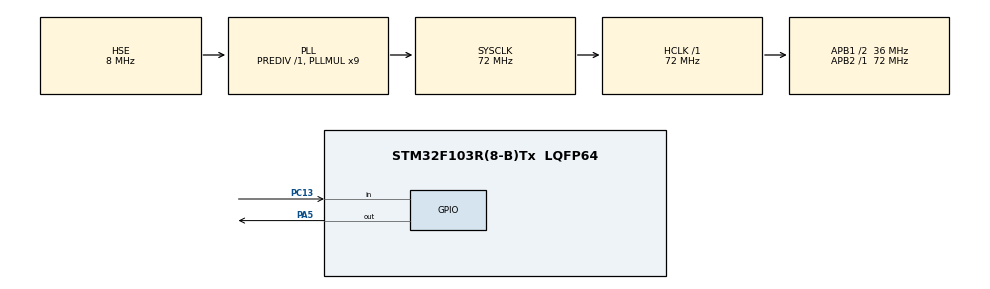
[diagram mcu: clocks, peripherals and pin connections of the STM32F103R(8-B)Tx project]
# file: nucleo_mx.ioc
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Mcu.Family=STM32F1
Mcu.Name=STM32F103R(8-B)Tx
Mcu.Package=LQFP64
NVIC.PriorityGroup=NVIC_PRIORITYGROUP_4
PA13.Mode=Serial_Wire
PA13.Signal=SYS_JTMS-SWDIO
PA14.Mode=Serial_Wire
PA14.Signal=SYS_JTCK-SWCLK
PA5.GPIO_Speed=GPIO_SPEED_FREQ_LOW
PA5.Signal=GPIO_Output
PC13-TAMPER-RTC.GPIO_PuPd=GPIO_NOPULL
PC13-TAMPER-RTC.Signal=GPIO_Input
PC14-OSC32_IN.Mode=LSE-External-Oscillator
PC14-OSC32_IN.Signal=RCC_OSC32_IN
PC15-OSC32_OUT.Mode=LSE-External-Oscillator
PC15-OSC32_OUT.Signal=RCC_OSC32_OUT
PD0-OSC_IN.Mode=HSE-External-Clock-Source
PD0-OSC_IN.Signal=RCC_OSC_IN
PD1-OSC_OUT.Mode=HSE-External-Clock-Source
PD1-OSC_OUT.Signal=RCC_OSC_OUT
ProjectManager.HeapSize=0x200
ProjectManager.StackSize=0x400
ProjectManager.TargetToolchain=Other Toolchains (GPDSC)
RCC.AHBFreq_Value=72000000
RCC.APB1CLKDivider=RCC_HCLK_DIV2
RCC.APB1Freq_Value=36000000
RCC.APB1TimFreq_Value=72000000
RCC.APB2Freq_Value=72000000
RCC.APB2TimFreq_Value=72000000
RCC.HCLKFreq_Value=72000000
RCC.PLLMUL=RCC_PLL_MUL9
RCC.PLLSourceVirtual=RCC_PLLSOURCE_HSE
RCC.SYSCLKFreq_VALUE=72000000
RCC.SYSCLKSource=RCC_SYSCLKSOURCE_PLLCLK
RCC.USBFreq_Value=72000000
board=NUCLEO-F103RB

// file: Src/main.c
/* USER CODE BEGIN Header */
/**
  ******************************************************************************
  * @file           : main.c
  * @brief          : Main program body
  ******************************************************************************
  * @attention
  *
  * <h2><center>&copy; Copyright (c) 2023 STMicroelectronics.
  * All rights reserved.</center></h2>
  *
  * This software component is licensed by ST under BSD 3-Clause license,
  * the "License"; You may not use this file except in compliance with the
  * License. You may obtain a copy of the License at:
  *                        opensource.org/licenses/BSD-3-Clause
  *
  ******************************************************************************
  */
/* USER CODE END Header */
#include "main.h"

void SystemClock_Config(void);
static void MX_GPIO_Init(void);

/* USER CODE BEGIN 0 */
#include <sfc/board.h>
#include <sfc/periphery/gpio.h>

// TODO: need better STM32CubeMX integration
typedef struct
{
    sfc_gpio_port_t dev;
    GPIO_TypeDef* core;
} stm32_gpio_t;

static void set(const sfc_gpio_port_t *port, uint32_t pin, sfc_gpio_pin_state_t state)
{
    const stm32_gpio_t *gpio = (stm32_gpio_t*)port;

    HAL_GPIO_WritePin(gpio->core, (1 << pin), state == SFC_GPIO_PIN_STATE_LOW  ? GPIO_PIN_RESET : GPIO_PIN_SET);
}

static sfc_gpio_pin_state_t get(const sfc_gpio_port_t *port, uint32_t pin)
{
    const stm32_gpio_t *gpio = (stm32_gpio_t*)port;

    GPIO_PinState state = HAL_GPIO_ReadPin(gpio->core, (1 << pin));

    return state == GPIO_PIN_SET ? SFC_GPIO_PIN_STATE_HIGH : SFC_GPIO_PIN_STATE_LOW;
}

static sfc_gpio_ops_t ops =
{
    .set = set,
    .get = get,
    .cfg = NULL
};
stm32_gpio_t portA = {{&portA, &ops}, GPIOA};
sfc_gpio_pin_t led_pin = {&portA.dev, 5};
stm32_gpio_t portC = {{&portC, &ops}, GPIOC};
sfc_gpio_pin_t btn_pin = {&portC.dev, 13};
#if 0
/* USER CODE END 0 */

int main(void)
{
  /* USER CODE BEGIN 1 */
}
#endif
void sfc_board_init()
{
  /* USER CODE END 1 */

  /* MCU Configuration--------------------------------------------------------*/

  /* Reset of all peripherals, Initializes the Flash interface and the Systick. */
  HAL_Init();

  /* Configure the system clock */
  SystemClock_Config();

  /* Initialize all configured peripherals */
  MX_GPIO_Init();
  /* USER CODE BEGIN 2 */

  sfc_gpio_assign_port(SFC_GPIO_CORE_1, &portA.dev);
  sfc_gpio_assign_port(SFC_GPIO_CORE_3, &portC.dev);
  /* USER CODE END 2 */

  /* Infinite loop */
  /* USER CODE BEGIN WHILE */
#if 0
  while (1)
  {
    /* USER CODE END WHILE */

    /* USER CODE BEGIN 3 */
  }
#endif
  /* USER CODE END 3 */
}

void SystemClock_Config(void)
{
  RCC_OscInitTypeDef RCC_OscInitStruct = {0};
  RCC_ClkInitTypeDef RCC_ClkInitStruct = {0};

  /** Initializes the RCC Oscillators according to the specified parameters
  * in the RCC_OscInitTypeDef structure.
  */
  RCC_OscInitStruct.OscillatorType = RCC_OSCILLATORTYPE_HSE;
  RCC_OscInitStruct.HSEState = RCC_HSE_BYPASS;
  RCC_OscInitStruct.HSEPredivValue = RCC_HSE_PREDIV_DIV1;
  RCC_OscInitStruct.HSIState = RCC_HSI_ON;
  RCC_OscInitStruct.PLL.PLLState = RCC_PLL_ON;
  RCC_OscInitStruct.PLL.PLLSource = RCC_PLLSOURCE_HSE;
  RCC_OscInitStruct.PLL.PLLMUL = RCC_PLL_MUL9;
  if (HAL_RCC_OscConfig(&RCC_OscInitStruct) != HAL_OK)
  {
    Error_Handler();
  }
  /** Initializes the CPU, AHB and APB buses clocks
  */
  RCC_ClkInitStruct.ClockType = RCC_CLOCKTYPE_HCLK|RCC_CLOCKTYPE_SYSCLK
                              |RCC_CLOCKTYPE_PCLK1|RCC_CLOCKTYPE_PCLK2;
  RCC_ClkInitStruct.SYSCLKSource = RCC_SYSCLKSOURCE_PLLCLK;
  RCC_ClkInitStruct.AHBCLKDivider = RCC_SYSCLK_DIV1;
  RCC_ClkInitStruct.APB1CLKDivider = RCC_HCLK_DIV2;
  RCC_ClkInitStruct.APB2CLKDivider = RCC_HCLK_DIV1;

  if (HAL_RCC_ClockConfig(&RCC_ClkInitStruct, FLASH_LATENCY_2) != HAL_OK)
  {
    Error_Handler();
  }
}

static void MX_GPIO_Init(void)
{
  GPIO_InitTypeDef GPIO_InitStruct = {0};

  /* GPIO Ports Clock Enable */
  __HAL_RCC_GPIOC_CLK_ENABLE();
  __HAL_RCC_GPIOD_CLK_ENABLE();
  __HAL_RCC_GPIOA_CLK_ENABLE();

  /*Configure GPIO pin Output Level */
  HAL_GPIO_WritePin(GPIOA, GPIO_PIN_5, GPIO_PIN_RESET);

  /*Configure GPIO pin : PC13 */
  GPIO_InitStruct.Pin = GPIO_PIN_13;
  GPIO_InitStruct.Mode = GPIO_MODE_INPUT;
  GPIO_InitStruct.Pull = GPIO_NOPULL;
  HAL_GPIO_Init(GPIOC, &GPIO_InitStruct);

  /*Configure GPIO pin : PA5 */
  GPIO_InitStruct.Pin = GPIO_PIN_5;
  GPIO_InitStruct.Mode = GPIO_MODE_OUTPUT_PP;
  GPIO_InitStruct.Pull = GPIO_NOPULL;
  GPIO_InitStruct.Speed = GPIO_SPEED_FREQ_LOW;
  HAL_GPIO_Init(GPIOA, &GPIO_InitStruct);

}

void Error_Handler(void)
{
  __disable_irq();
  while (1)
  {
  }
}

/************************ (C) COPYRIGHT STMicroelectronics *****END OF FILE****/
